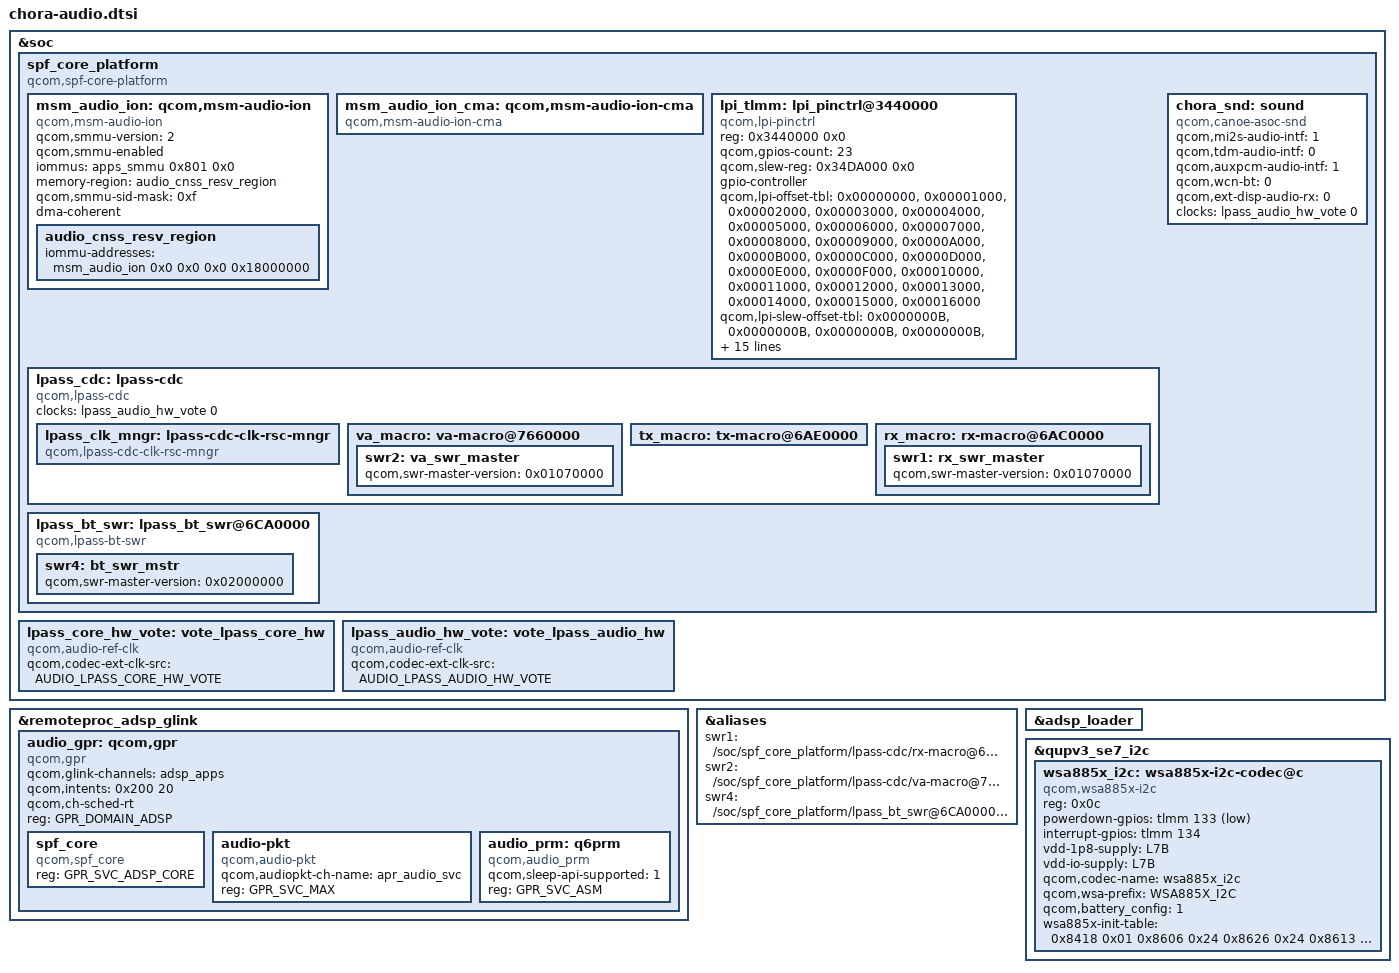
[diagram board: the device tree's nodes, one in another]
//
/* Copyright (c) Qualcomm Technologies, Inc. and/or its subsidiaries.
 *  SPDX-License-Identifier: BSD-3-Clause
 */

#include <bindings/qcom,audio-ext-clk.h>
#include <dt-bindings/gpio/gpio.h>
#include <bindings/qcom,gpr.h>
#include "msm-audio-lpass.dtsi"

&soc {
	spf_core_platform: spf_core_platform {
		compatible = "qcom,spf-core-platform";
	};

	lpass_core_hw_vote: vote_lpass_core_hw {
		compatible = "qcom,audio-ref-clk";
		qcom,codec-ext-clk-src = <AUDIO_LPASS_CORE_HW_VOTE>;
		#clock-cells = <1>;
	};

	lpass_audio_hw_vote: vote_lpass_audio_hw {
		compatible = "qcom,audio-ref-clk";
		qcom,codec-ext-clk-src = <AUDIO_LPASS_AUDIO_HW_VOTE>;
		#clock-cells = <1>;
	};
};

&remoteproc_adsp_glink {
	audio_gpr: qcom,gpr {
		compatible = "qcom,gpr";
		qcom,glink-channels = "adsp_apps";
		qcom,intents = <0x200 20>;
		qcom,ch-sched-rt;
		reg = <GPR_DOMAIN_ADSP>;

		spf_core {
			compatible = "qcom,spf_core";
			reg = <GPR_SVC_ADSP_CORE>;
		};

		audio-pkt {
			compatible = "qcom,audio-pkt";
			qcom,audiopkt-ch-name = "apr_audio_svc";
			reg = <GPR_SVC_MAX>;
		};

		audio_prm: q6prm {
			compatible = "qcom,audio_prm";
			qcom,sleep-api-supported = <1>;
			reg = <GPR_SVC_ASM>;
		};
	};
};

&spf_core_platform {
	#address-cells = <2>;
	#size-cells = <2>;
	msm_audio_ion: qcom,msm-audio-ion {
		compatible = "qcom,msm-audio-ion";
		qcom,smmu-version = <2>;
		qcom,smmu-enabled;
		iommus = <&apps_smmu 0x801 0x0>;
		memory-region = <&audio_cnss_resv_region>;
		qcom,smmu-sid-mask = /bits/ 64 <0xf>;
		dma-coherent;

		audio_cnss_resv_region: audio_cnss_resv_region {
			iommu-addresses = <&msm_audio_ion 0x0 0x0 0x0 0x18000000>;
		};
	};

	msm_audio_ion_cma: qcom,msm-audio-ion-cma {
		compatible = "qcom,msm-audio-ion-cma";
	};

	lpi_tlmm: lpi_pinctrl@3440000 {
		compatible = "qcom,lpi-pinctrl";
		reg = <0x3440000 0x0>;
		qcom,gpios-count = <23>;
		qcom,slew-reg = <0x34DA000 0x0>;
		gpio-controller;
		#gpio-cells = <2>;
		qcom,lpi-offset-tbl = <0x00000000>, <0x00001000>,
					<0x00002000>, <0x00003000>,
					<0x00004000>, <0x00005000>,
					<0x00006000>, <0x00007000>,
					<0x00008000>, <0x00009000>,
					<0x0000A000>, <0x0000B000>,
					<0x0000C000>, <0x0000D000>,
					<0x0000E000>, <0x0000F000>,
					<0x00010000>, <0x00011000>,
					<0x00012000>, <0x00013000>,
					<0x00014000>, <0x00015000>,
					<0x00016000>;

		qcom,lpi-slew-offset-tbl = <0x0000000B>, <0x0000000B>,
					<0x0000000B>, <0x0000000B>,
					<0x0000000B>, <0x0000000B>,
					<0x0000000B>, <0x0000000B>,
					<0x0000000B>, <0x0000000B>,
					<0x0000000B>, <0x0000000B>,
					<0x0000000B>, <0x0000000B>,
					<0x0000000B>, <0x0000000B>,
					<0x0000000B>, <0x0000000B>,
					<0x0000000B>, <0x0000000B>,
					<0x0000000B>, <0x0000000B>,
					<0x0000000B>;

		qcom,lpi-slew-base-tbl = <0x3440000>, <0x3441000>,
					<0x3442000>, <0x3443000>,
					<0x3444000>, <0x3445000>,
					<0x3446000>, <0x3447000>,
					<0x3448000>, <0x3449000>,
					<0x344A000>, <0x344B000>,
					<0x344C000>, <0x344D000>,
					<0x344E000>, <0x344F000>,
					<0x3450000>, <0x3451000>,
					<0x3452000>, <0x3453000>,
					<0x3454000>, <0x3455000>,
					<0x3456000>;

		clock-names = "lpass_audio_hw_vote";
		clocks = <&lpass_audio_hw_vote 0>;
	};

	lpass_cdc: lpass-cdc {
		compatible = "qcom,lpass-cdc";
		clock-names = "lpass_audio_hw_vote";
		clocks = <&lpass_audio_hw_vote 0>;
		lpass_clk_mngr: lpass-cdc-clk-rsc-mngr {
			compatible = "qcom,lpass-cdc-clk-rsc-mngr";
		};

		va_macro: va-macro@7660000 {
			swr2: va_swr_master {
				qcom,swr-master-version = <0x01070000>;
			};
		};

		tx_macro: tx-macro@6AE0000 {
		};

		rx_macro: rx-macro@6AC0000 {
			swr1: rx_swr_master {
				qcom,swr-master-version = <0x01070000>;
			};
		};
	};

	lpass_bt_swr: lpass_bt_swr@6CA0000 {
		compatible = "qcom,lpass-bt-swr";
		swr4: bt_swr_mstr {
				qcom,swr-master-version = <0x02000000>;
		};
	};

	chora_snd: sound {
		compatible = "qcom,canoe-asoc-snd";
		qcom,mi2s-audio-intf = <1>;
		qcom,tdm-audio-intf = <0>;
		qcom,auxpcm-audio-intf = <1>;
		qcom,wcn-bt = <0>;
		qcom,ext-disp-audio-rx = <0>;
		clock-names = "lpass_audio_hw_vote";
		clocks = <&lpass_audio_hw_vote 0>;
	};

};

&aliases {
	swr1 = "/soc/spf_core_platform/lpass-cdc/rx-macro@6AC0000/rx_swr_master";
	swr2 = "/soc/spf_core_platform/lpass-cdc/va-macro@7660000/va_swr_master";
	swr4 = "/soc/spf_core_platform/lpass_bt_swr@6CA0000/bt_swr_mstr";
};

&adsp_loader {
	/delete-property/ qcom,adsp-state;
};

&qupv3_se7_i2c {
	status = "okay";
	wsa885x_i2c: wsa885x-i2c-codec@c {
		compatible = "qcom,wsa885x-i2c";
		reg = <0x0c>;
		powerdown-gpios = <&tlmm 133 GPIO_ACTIVE_LOW>;
		interrupt-gpios = <&tlmm 134 GPIO_ACTIVE_HIGH>;
		vdd-1p8-supply = <&L7B>;
		vdd-io-supply = <&L7B>;
		qcom,codec-name = "wsa885x_i2c";
		qcom,wsa-prefix = "WSA885X_I2C";
		qcom,battery_config = <1>;
		wsa885x-init-table =
			<0x8418 0x01
			0x8606 0x24  /* CDC_RX0_RX_PATH_CTL - CLK_EN(1) */
			0x8626 0x24  /* CDC_RX1_RX_PATH_CTL - CLK_EN(1) */
			0x8613 0x1   /* RX0_RX_PATH_DSMDEM_CTL - DSMDEM_CLK_EN(1) */
			0x8633 0x1   /* RX1_RX_PATH_DSMDEM_CTL - DSMDEM_CLK_EN(1) */
			0x8640 0x1   /* CDC_COMPANDER0_CTL0 - CLK_EN(1) */
			0x8660 0x1   /* CDC_COMPANDER1_CTL0 - CLK_EN(1) */
			0x86A1 0x14  /* CDC_VSENSE0_SPKR_PROT_PATH_CTL - CLK_EN(1) */
			0x86B1 0x14  /* CDC_VSENSE1_SPKR_PROT_PATH_CTL - CLK_EN(1)*/
			0x86A9 0x14  /* CDC_ISENSE0_SPKR_PROT_PATH_CTL - CLK_EN(1) */
			0x86B9 0x14  /* CDC_ISENSE1_SPKR_PROT_PATH_CTL - CLK_EN(1) */
			0x841C 0xF   /* DIG_CTRL0_CDC_CLK_CTL  - SYS_CLOCK_EN(1) */
			0x841C 0x4F  /* DIG_CTRL0_CDC_CLK_CTL - FSM_INTP_CG_DISABLE */
			0x8470 0x2   /* DIG_CTRL0_CDC_RXTX_FSCNT_CTL - FS_CNT_CLR(1) */
			0x8470 0x0   /* DIG_CTRL0_CDC_RXTX_FSCNT_CTL - FS_CNT_CLR(0) */
			0x8470 0x1   /* DIG_CTRL0_CDC_RXTX_FSCNT_CTL - FS_CNT_EN(1) */
			0x0004 0x1   /* SMP_AMP_CTRL_STEREO_CMT_GRP_MASK - CMT_GRP_MASK(1) */
			0x8602 0x60  /* CDC_RX0_RX_PATH_CFG1 - HPF_EN(0) */
			0x8622 0x60  /* CDC_RX1_RX_PATH_CFG1 - HPF_EN(0) */
			0x8108 0xA5  /* PANDEIRO_ANA_TOP_SPK_TOP_PWRSTG_CH1_CTRL3 */
			0x810E 0xA5  /* PANDEIRO_ANA_TOP_SPK_TOP_PWRSTG_CH2_CTRL3 */
			0x80CA 0x85  /* PANDEIRO_ANA_TOP_IVSENSE_ADC_MODE_CTL2 - SPARE_BITS_0(Sets LDO to 1.6V) */
			0x80CB 0xC   /* PANDEIRO_ANA_TOP_IVSENSE_ADC_MODE_CTL3 - ADC_VREF_VCTL_I(Sets VREF_I to 1.35V) */
			0x80CB 0xE   /* PANDEIRO_ANA_TOP_IVSENSE_ADC_MODE_CTL3 - ADC_VREF_VCTL_I(Sets VREF_I to 1.35V) */
			0x80CC 0xC   /* PANDEIRO_ANA_TOP_IVSENSE_ADC_REF_CTL - ADC_VREF_VCTL_V(Sets VREF_V to 1.35V) */
			0x84B4 0x1   /* PANDEIRO_DIG_CTRL0_GAIN_RAMP0_CTL1 - ANA_BYPASS(1) */
			0x84B7 0x1   /* PANDEIRO_DIG_CTRL0_GAIN_RAMP1_CTL1 - ANA_BYPASS(1) */
			0x8601 0x88  /* CDC_RX0_RX_PATH_CFG0 - DLY_ZN_EN(1) */
			0x8601 0x89  /* CDC_RX0_RX_PATH_CFG0 - PH_EQ_EN */
			0x8621 0x88  /* CDC_RX1_RX_PATH_CFG0 - DLY_ZN_EN(1) */
			0x8621 0x89  /* CDC_RX1_RX_PATH_CFG0 - PH_EQ_EN */
			0x805B 0x82  /* PANDEIRO_ANA_TOP_BOOST_STB_CTRL2 */
			0x805C 0x34  /* PANDEIRO_ANA_TOP_BOOST_STB_CTRL3 */
			0x8065 0x41  /* PANDEIRO_ANA_TOP_BOOST_PWRSTAGE_CTRL2 */
			0x8067 0x7F  /* PANDEIRO_ANA_TOP_BOOST_PWRSTAGE_CTRL4 */
			0x86CD 0x50  /* CDC_CLSH_V1P8_BP_CTL1 */
			0x86CC 0x6C  /* CDC_CLSH_V1P8_BP_CTL0 */
			0x86C7 0xD   /* CDC_CLSH_CLSH_SIG_DP_CTL0 */
			0x86C3 0x3   /* CDC_CLSH_CLSH_V_HD_PA */
			0x8423 0x5   /* PANDEIRO_DIG_CTRL0_POWER_FSM_CTL0 */
			0x800D 0x20   /* PANDEIRO_DIG_CTRL0_POWER_FSM_CTL0 BST_CLK_FLIP_EN(Boost enable FSM issue(Work around for I2S mode, flip boost div2 clk)) */
			0x810B 0x45  /* PANDEIRO_ANA_TOP_SPK_TOP_PWRSTG_CH1_TUNE3 */
			0x8111 0x45  /* PANDEIRO_ANA_TOP_SPK_TOP_PWRSTG_CH2_TUNE3 */
			0x86CE 0x5   /* CDC_CLSH_V1P8_BP_CTL2 - BP_CNT  */
			0x8024 0x35  /* PANDEIRO_ANA_TOP_BG_TVP_UVLO1_PROG - VTH 2.1v */
			0x8025 0x21  /* PANDEIRO_ANA_TOP_BG_TVP_UVLO2_PROG - VTH 2.0v */
			0x805E 0xC7  /* PANDEIRO_ANA_TOP_BOOST_BYP_CTRL2 */
			0x805F 0x11  /* PANDEIRO_ANA_TOP_BOOST_BYP_CTRL3 */
			0x80D0 0x80 /* PANDEIRO_ANA_TOP_IVSENSE_ADC_CDAC_CAL_CTL2 */
			0x813C 0x08 /* PANDEIRO_ANA_TOP_SPK_TOP_SPARE3 */
			0x842B 0x47 /* PANDEIRO_DIG_CTRL0_PA0_FSM_CTL1 - SILENT_STATE_IVS_EN */
			0x8435 0x47 /* PANDEIRO_DIG_CTRL0_PA1_FSM_CTL1 - SILENT_STATE_IVS_EN */
			0x8647 0x34 /* CDC_COMPANDER0_CTL7 - AGAIN_DELAY */
			0x8667 0x34 /* CDC_COMPANDER1_CTL7 - AGAIN_DELAY */
			0x8458 0x79 /* PANDEIRO_DIG_CTRL0_VBAT_THRM_FLT_CTL - VBAT_COEF_SEL */
			0x800D 0x08>;
	};
};
